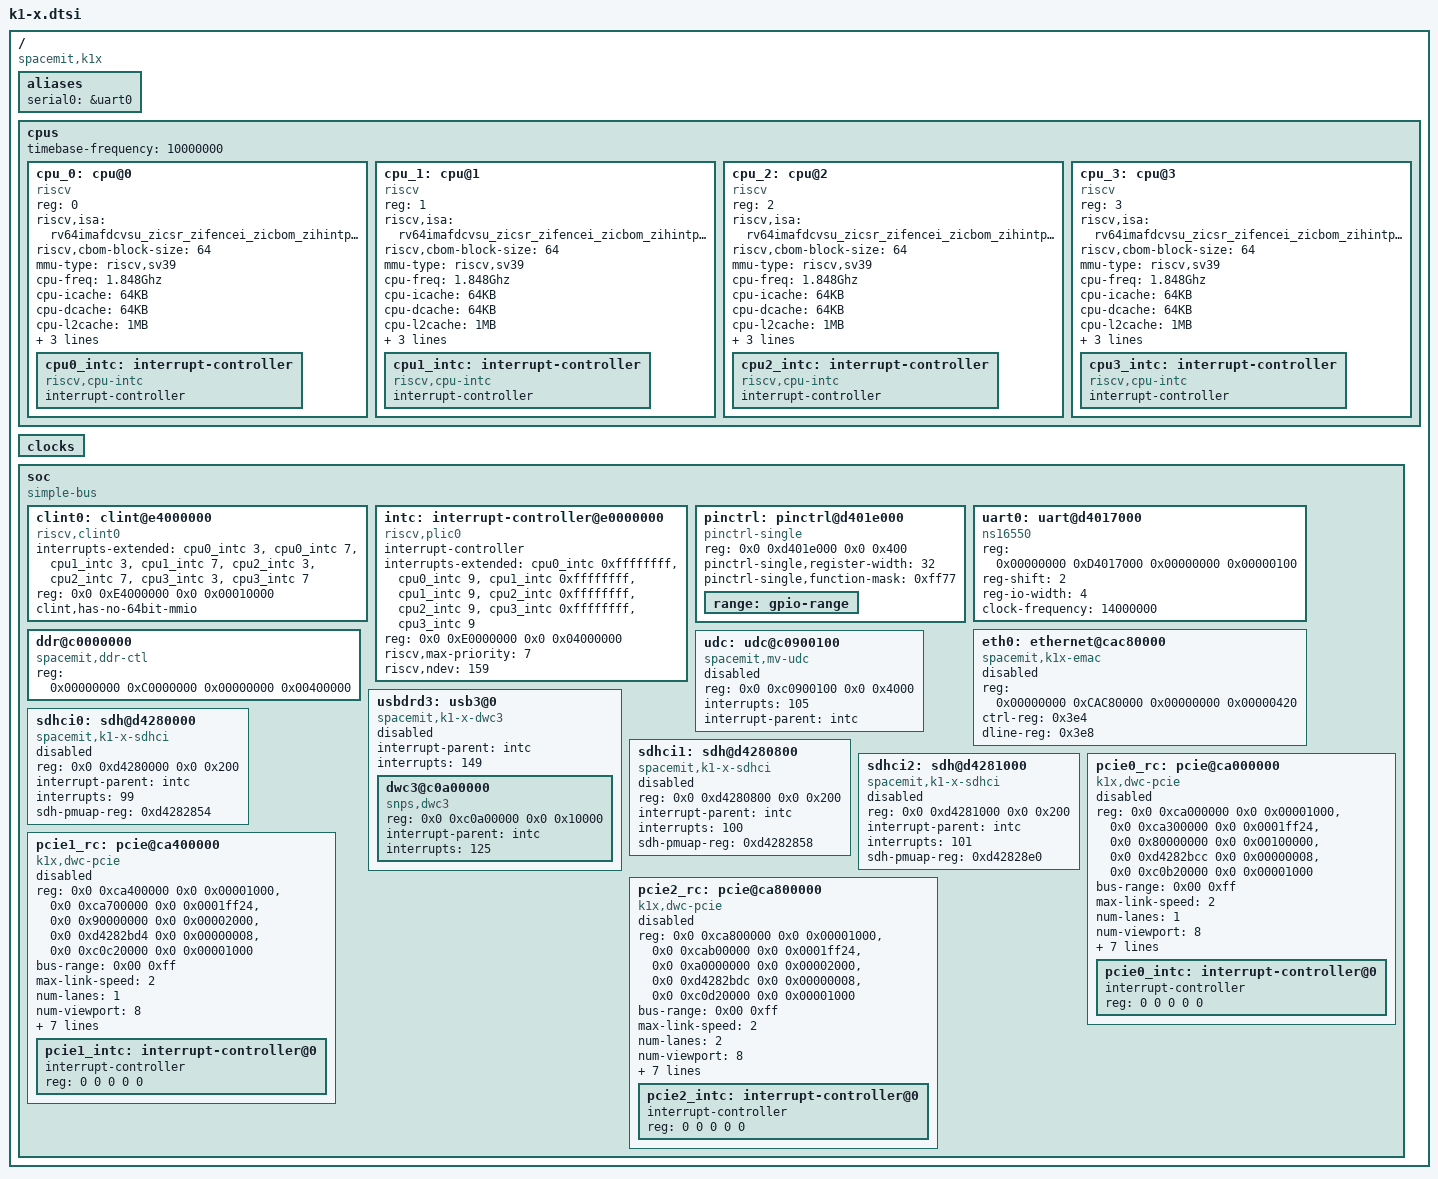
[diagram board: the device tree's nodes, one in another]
// SPDX-License-Identifier: (GPL-2.0 OR MIT)
/* Copyright (c) 2023 Spacemit, Inc */

/dts-v1/;
/ {
	compatible = "spacemit,k1x", "riscv";
	#address-cells = <2>;
	#size-cells = <2>;

	aliases {
		serial0 = &uart0;
	};

	cpus: cpus {
		#address-cells = <1>;
		#size-cells = <0>;
		timebase-frequency = <10000000>;
		u-boot,dm-spl;
		cpu_0: cpu@0 {
			device_type = "cpu";
			reg = <0>;
			status = "okay";
			compatible = "riscv";
			riscv,isa = "rv64imafdcvsu_zicsr_zifencei_zicbom_zihintpause_zba_zbb_zbc_zbs_svpbmt";
			riscv,cbom-block-size = <64>;
			mmu-type = "riscv,sv39";
			cpu-freq = "1.848Ghz";
			cpu-icache = "64KB";
			cpu-dcache = "64KB";
			cpu-l2cache = "1MB";
			cpu-tlb = "1024 4-ways";
			cpu-cacheline = "64Bytes";
			cpu-vector = "0.7.1";
			u-boot,dm-spl;
			cpu0_intc: interrupt-controller {
				#interrupt-cells = <1>;
				compatible = "riscv,cpu-intc";
				interrupt-controller;
				u-boot,dm-spl;
			};
		};
		cpu_1: cpu@1 {
			device_type = "cpu";
			reg = <1>;
			status = "okay";
			compatible = "riscv";
			riscv,isa = "rv64imafdcvsu_zicsr_zifencei_zicbom_zihintpause_zba_zbb_zbc_zbs_svpbmt";
			riscv,cbom-block-size = <64>;
			mmu-type = "riscv,sv39";
			cpu-freq = "1.848Ghz";
			cpu-icache = "64KB";
			cpu-dcache = "64KB";
			cpu-l2cache = "1MB";
			cpu-tlb = "1024 4-ways";
			cpu-cacheline = "64Bytes";
			cpu-vector = "0.7.1";
			u-boot,dm-spl;

			cpu1_intc: interrupt-controller {
				#interrupt-cells = <1>;
				compatible = "riscv,cpu-intc";
				interrupt-controller;
				u-boot,dm-spl;
			};
		};
		cpu_2: cpu@2 {
			device_type = "cpu";
			reg = <2>;
			status = "okay";
			compatible = "riscv";
			riscv,isa = "rv64imafdcvsu_zicsr_zifencei_zicbom_zihintpause_zba_zbb_zbc_zbs_svpbmt";
			riscv,cbom-block-size = <64>;
			mmu-type = "riscv,sv39";
			cpu-freq = "1.848Ghz";
			cpu-icache = "64KB";
			cpu-dcache = "64KB";
			cpu-l2cache = "1MB";
			cpu-tlb = "1024 4-ways";
			cpu-cacheline = "64Bytes";
			cpu-vector = "0.7.1";
			u-boot,dm-spl;

			cpu2_intc: interrupt-controller {
				#interrupt-cells = <1>;
				compatible = "riscv,cpu-intc";
				interrupt-controller;
				u-boot,dm-spl;
			};
		};
		cpu_3: cpu@3 {
			device_type = "cpu";
			reg = <3>;
			status = "okay";
			compatible = "riscv";
			riscv,isa = "rv64imafdcvsu_zicsr_zifencei_zicbom_zihintpause_zba_zbb_zbc_zbs_svpbmt";
			riscv,cbom-block-size = <64>;
			mmu-type = "riscv,sv39";
			cpu-freq = "1.848Ghz";
			cpu-icache = "64KB";
			cpu-dcache = "64KB";
			cpu-l2cache = "1MB";
			cpu-tlb = "1024 4-ways";
			cpu-cacheline = "64Bytes";
			cpu-vector = "0.7.1";
			u-boot,dm-spl;

			cpu3_intc: interrupt-controller {
				#interrupt-cells = <1>;
				compatible = "riscv,cpu-intc";
				interrupt-controller;
				u-boot,dm-spl;
			};
		};
	};

	clocks {
		#address-cells = <0x2>;
		#size-cells = <0x2>;
		ranges;
	};

	soc {
		compatible = "simple-bus";
		#address-cells = <2>;
		#size-cells = <2>;
		ranges;
		u-boot,dm-spl;

		clint0: clint@e4000000 {
			compatible = "riscv,clint0";
			interrupts-extended = <
				&cpu0_intc  3 &cpu0_intc  7
				&cpu1_intc  3 &cpu1_intc  7
				&cpu2_intc  3 &cpu2_intc  7
				&cpu3_intc  3 &cpu3_intc  7
			>;
			reg = <0x0 0xE4000000 0x0 0x00010000>;
			clint,has-no-64bit-mmio;
			u-boot,dm-spl;
		};

		intc: interrupt-controller@e0000000 {
			#interrupt-cells = <1>;
			compatible = "riscv,plic0";
			interrupt-controller;
			interrupts-extended = <
				&cpu0_intc 0xffffffff &cpu0_intc 9
				&cpu1_intc 0xffffffff &cpu1_intc 9
				&cpu2_intc 0xffffffff &cpu2_intc 9
				&cpu3_intc 0xffffffff &cpu3_intc 9
			>;
			reg = <0x0 0xE0000000 0x0 0x04000000>;
			reg-names = "control";
			riscv,max-priority = <7>;
			riscv,ndev = <159>;
		};

		pinctrl: pinctrl@d401e000 {
			compatible = "pinctrl-single";
			reg = <0x0 0xd401e000 0x0 0x400>;
			#address-cells = <1>;
			#size-cells = <1>;
			#pinctrl-cells = <2>;
			#gpio-range-cells = <3>;

			pinctrl-single,register-width = <32>;
			pinctrl-single,function-mask = <0xff77>;

			range: gpio-range {
				#pinctrl-single,gpio-range-cells = <3>;
			};
		};

		uart0: uart@d4017000 {
			u-boot,dm-spl;
			compatible = "ns16550";
			reg = <0x00000000 0xD4017000 0x00000000 0x00000100>;
			reg-shift = <2>;
			reg-io-width = <4>;
			clock-frequency = <14000000>;
		};

		ddr@c0000000 {
			u-boot,dm-spl;
			compatible = "spacemit,ddr-ctl";
			reg = <0x00000000 0xC0000000 0x00000000 0x00400000>;
		};

		eth0: ethernet@cac80000 {
			compatible = "spacemit,k1x-emac";
			reg = <0x00000000 0xCAC80000 0x00000000 0x00000420>;
			ctrl-reg = <0x3e4>;
			dline-reg = <0x3e8>;
			status = "disabled";
		};

		udc: udc@c0900100 {
			compatible = "spacemit,mv-udc";
			reg = <0x0 0xc0900100 0x0 0x4000>;
			interrupts = <105>;
			interrupt-parent = <&intc>;
			status = "disabled";
		};

		usbdrd3: usb3@0 {
			compatible = "spacemit,k1-x-dwc3";
			#address-cells = <2>;
			#size-cells = <2>;
			//resets = <&reset RESET_USB31>;
			//reset-names = "ctl_rst";
			interrupt-parent = <&intc>;
			interrupts = <149>;
			ranges;
			status = "disabled";

			dwc3@c0a00000 {
				compatible = "snps,dwc3";
				reg = <0x0 0xc0a00000 0x0 0x10000>;
				interrupt-parent = <&intc>;
				interrupts = <125>;
			};
		};

		sdhci0: sdh@d4280000 {
			compatible = "spacemit,k1-x-sdhci";
			reg = <0x0 0xd4280000 0x0 0x200>;
			interrupt-parent = <&intc>;
			interrupts = <99>;
			sdh-pmuap-reg = <0xd4282854>;
			status = "disabled";
		};

		sdhci1: sdh@d4280800 {
			compatible = "spacemit,k1-x-sdhci";
			reg = <0x0 0xd4280800 0x0 0x200>;
			interrupt-parent = <&intc>;
			interrupts = <100>;
			sdh-pmuap-reg = <0xd4282858>;
			status = "disabled";
		};

		sdhci2: sdh@d4281000 {
			compatible = "spacemit,k1-x-sdhci";
			reg = <0x0 0xd4281000 0x0 0x200>;
			interrupt-parent = <&intc>;
			interrupts = <101>;
			sdh-pmuap-reg = <0xd42828e0>;
			status = "disabled";
		};

		pcie0_rc: pcie@ca000000 {
			compatible = "k1x,dwc-pcie";
			reg = <0x0 0xca000000 0x0 0x00001000>, /* dbi */
			      <0x0 0xca300000 0x0 0x0001ff24>, /* atu registers */
			      <0x0 0x80000000 0x0 0x00100000>, /* config space */
			      <0x0 0xd4282bcc 0x0 0x00000008>, /* k1x soc config addr */
			      <0x0 0xc0b20000 0x0 0x00001000>; /* phy ahb */
			reg-names = "dbi", "atu", "config", "k1x_conf", "phy_ahb";

			//clocks = <&clock CLK_PCIE0>;
			clock-names = "pcie-clk";

			bus-range = <0x00 0xff>;
			max-link-speed = <2>;
			num-lanes = <1>;
			num-viewport = <8>;
			device_type = "pci";
			#address-cells = <3>;
			#size-cells = <2>;
			ranges = <0x81000000 0x0 0x80100000 0 0x80100000 0x0 0x100000>,
				 <0x82000000 0x0 0x80200000 0 0x80200000 0x0 0x0fe00000>;

			interrupts = <141>, <145>;
			interrupt-parent = <&intc>;
			#interrupt-cells = <1>;
			interrupt-map-mask = <0 0 0 0x7>;
			interrupt-map = <0000 0 0 1 &pcie0_intc 1>, /* int_a */
					<0000 0 0 2 &pcie0_intc 2>, /* int_b */
					<0000 0 0 3 &pcie0_intc 3>, /* int_c */
					<0000 0 0 4 &pcie0_intc 4>; /* int_d */
			linux,pci-domain = <0>;
			status = "disabled";
			pcie0_intc: interrupt-controller@0 {
				interrupt-controller;
				reg = <0 0 0 0 0>;
				#address-cells = <0>;
				#interrupt-cells = <1>;
			};
		};

		pcie1_rc: pcie@ca400000 {
			compatible = "k1x,dwc-pcie";
			reg = <0x0 0xca400000 0x0 0x00001000>, /* dbi */
			      <0x0 0xca700000 0x0 0x0001ff24>, /* atu registers */
			      <0x0 0x90000000 0x0 0x00002000>, /* config space */
			      <0x0 0xd4282bd4 0x0 0x00000008>, /* k1x soc config addr */
			      <0x0 0xc0c20000 0x0 0x00001000>; /* phy ahb */
			reg-names = "dbi", "atu", "config", "k1x_conf", "phy_ahb";

			//clocks = <&clock CLK_PCIE1>;
			clock-names = "pcie-clk";

			bus-range = <0x00 0xff>;
			max-link-speed = <2>;
			num-lanes = <1>;
			num-viewport = <8>;
			device_type = "pci";
			#address-cells = <3>;
			#size-cells = <2>;
			ranges = <0x01000000 0x0 0x90002000 0 0x90002000 0x0 0x100000>,
				 <0x02000000 0x0 0x90102000 0 0x90102000 0x0 0x10000000>;

			interrupts = <142>, <146>;
			interrupt-parent = <&intc>;
			#interrupt-cells = <1>;
			interrupt-map-mask = <0 0 0 0x7>;
			interrupt-map = <0000 0 0 1 &pcie1_intc 1>, /* int_a */
					<0000 0 0 2 &pcie1_intc 2>, /* int_b */
					<0000 0 0 3 &pcie1_intc 3>, /* int_c */
					<0000 0 0 4 &pcie1_intc 4>; /* int_d */
			linux,pci-domain = <0>;
			status = "disabled";
			pcie1_intc: interrupt-controller@0 {
				interrupt-controller;
				reg = <0 0 0 0 0>;
				#address-cells = <0>;
				#interrupt-cells = <1>;
			};
		};

		pcie2_rc: pcie@ca800000 {
			compatible = "k1x,dwc-pcie";
			reg = <0x0 0xca800000 0x0 0x00001000>, /* dbi */
			      <0x0 0xcab00000 0x0 0x0001ff24>, /* atu registers */
			      <0x0 0xa0000000 0x0 0x00002000>, /* config space */
			      <0x0 0xd4282bdc 0x0 0x00000008>, /* k1x soc config addr */
			      <0x0 0xc0d20000 0x0 0x00001000>; /* phy ahb */
			reg-names = "dbi", "atu", "config", "k1x_conf", "phy_ahb";

			//clocks = <&clock CLK_PCIE2>;
			clock-names = "pcie-clk";

			bus-range = <0x00 0xff>;
			max-link-speed = <2>;
			num-lanes = <2>;
			num-viewport = <8>;
			device_type = "pci";
			#address-cells = <3>;
			#size-cells = <2>;
			ranges = <0x01000000 0x0 0xa0002000 0 0xa0002000 0x0 0x100000>,
				 <0x02000000 0x0 0xa0102000 0 0xa0102000 0x0 0x10000000>;

			interrupts = <143>, <147>;
			interrupt-parent = <&intc>;
			#interrupt-cells = <1>;
			interrupt-map-mask = <0 0 0 0x7>;
			interrupt-map = <0000 0 0 1 &pcie2_intc 1>, /* int_a */
					<0000 0 0 2 &pcie2_intc 2>, /* int_b */
					<0000 0 0 3 &pcie2_intc 3>, /* int_c */
					<0000 0 0 4 &pcie2_intc 4>; /* int_d */
			linux,pci-domain = <2>;
			status = "disabled";
			pcie2_intc: interrupt-controller@0 {
				interrupt-controller;
				reg = <0 0 0 0 0>;
				#address-cells = <0>;
				#interrupt-cells = <1>;
			};
		};
	};
};

